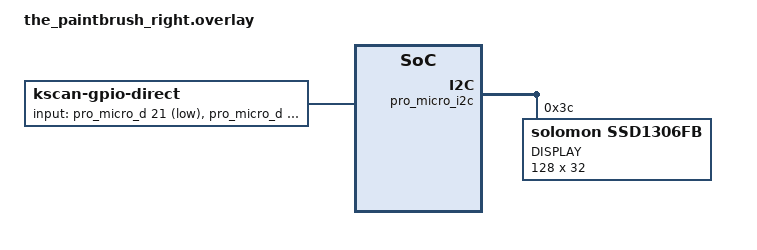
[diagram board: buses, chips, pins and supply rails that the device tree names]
/*
 * Copyright (c) 2021 Mike "KemoNine" Crosson
 *
 * SPDX-License-Identifier: MIT
 */

#include <dt-bindings/zmk/matrix_transform.h>

&pro_micro_i2c {
	status = "okay";

	oled: ssd1306@3c {
		compatible = "solomon,ssd1306fb";
		reg = <0x3c>;
		label = "DISPLAY";
		width = <128>;
		height = <32>;
        sda-pin = <20>; // oled 20 - nice!nano pin 107 https://www.reddit.com/r/zmk/comments/160l9ur/help_zmk_nicenano_v2_with_an_i2c_128x32_oled_oled/ 
        scl-pin = <22>; // oled 22 - nice!nano pin 102 
        segment-offset = <0>;
		page-offset = <0>;
		display-offset = <0>;
		multiplex-ratio = <31>;
		segment-remap;
		com-invdir;
		com-sequential;
		prechargep = <0x22>;
	};
};

/ {
	chosen {
		zmk,kscan = &kscan0;
		zephyr,display = &oled;
	};

	kscan0: kscan_0 {
		compatible = "zmk,kscan-gpio-direct";

		label = "KSCAN";

		input-gpios
 //ARTS
    = <&pro_micro_d 21 (GPIO_ACTIVE_LOW | GPIO_PULL_UP)>
			, <&pro_micro_d 20 (GPIO_ACTIVE_LOW | GPIO_PULL_UP)>
			, <&pro_micro_d 19 (GPIO_ACTIVE_LOW | GPIO_PULL_UP)>
			, <&pro_micro_d 18 (GPIO_ACTIVE_LOW | GPIO_PULL_UP)>

//EYIO (in reverse order)
			, <&pro_micro_d 10 (GPIO_ACTIVE_LOW | GPIO_PULL_UP)>
			, <&pro_micro_d 16 (GPIO_ACTIVE_LOW | GPIO_PULL_UP)>
			, <&pro_micro_d 14 (GPIO_ACTIVE_LOW | GPIO_PULL_UP)>
            , <&pro_micro_d 15 (GPIO_ACTIVE_LOW | GPIO_PULL_UP)>
			;

	};
};
